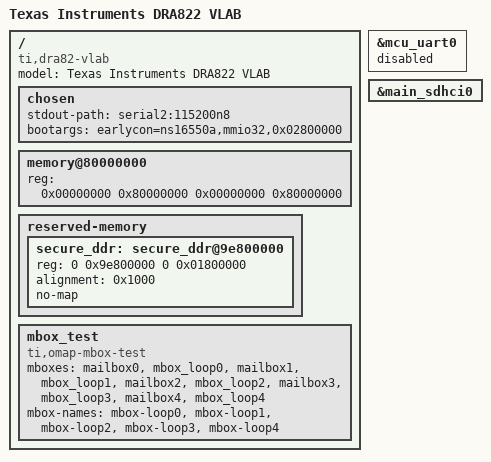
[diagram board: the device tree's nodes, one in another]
// SPDX-License-Identifier: GPL-2.0
/*
 * Copyright (C) 2016-2018 Texas Instruments Incorporated - http://www.ti.com/
 */

/dts-v1/;

#include "k3-dra82.dtsi"

/ {
	compatible =  "ti,dra82-vlab", "ti,dra822";
	model = "Texas Instruments DRA822 VLAB";

	chosen {
		stdout-path = "serial2:115200n8";
		bootargs = "earlycon=ns16550a,mmio32,0x02800000";
	};

	memory@80000000 {
		device_type = "memory";
		/* 2G RAM */
		reg = <0x00000000 0x80000000 0x00000000 0x80000000>;

	};

	reserved-memory {
		#address-cells = <2>;
		#size-cells = <2>;
		ranges;
		secure_ddr: secure_ddr@9e800000 {
			reg = <0 0x9e800000 0 0x01800000>; /* for OP-TEE */
			alignment = <0x1000>;
			no-map;
		};
	};

	mbox_test {
		compatible = "ti,omap-mbox-test";
		mboxes = <&mailbox0 &mbox_loop0>, <&mailbox1 &mbox_loop1>,
			 <&mailbox2 &mbox_loop2>, <&mailbox3 &mbox_loop3>,
			 <&mailbox4 &mbox_loop4>;
		mbox-names = "mbox-loop0", "mbox-loop1",
			     "mbox-loop2", "mbox-loop3", "mbox-loop4";
	};
};

&mcu_uart0 {
	/* Wakeup UART is used by System firmware */
	status = "disabled";
};

#include "k3-dss-640x480-port0-oldi.dtsi"
#include "k3-dss-640x480-port1-dpi.dtsi"

&main_sdhci0 {
	status = "okay";
};
